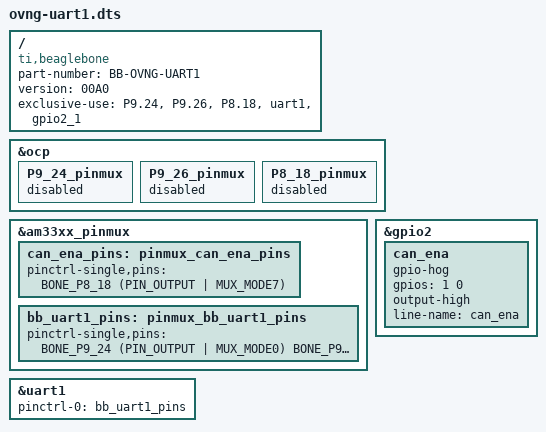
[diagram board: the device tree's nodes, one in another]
/*
 * Copyright (C) 2013 CircuitCo
 *
 * Virtual cape for UART1 on connector pins P9.24 P9.26
 *
 * This program is free software; you can redistribute it and/or modify
 * it under the terms of the GNU General Public License version 2 as
 * published by the Free Software Foundation.
 */

/dts-v1/;
/plugin/;

#include <dt-bindings/board/am335x-bbw-bbb-base.h>
#include <dt-bindings/pinctrl/am33xx.h>

/ {
	compatible = "ti,beaglebone", "ti,beaglebone-black", "ti,beaglebone-green", "ti,beaglebone-green-wireless";

	// identification
	part-number = "BB-OVNG-UART1";
	version = "00A0";

	// resources this cape uses
	exclusive-use =
		"P9.24",	// uart1_txd
		"P9.26",	// uart1_rxd
		"P8.18",	// gpio2_1: can_ena

		"uart1",	// hardware ip used
		"gpio2_1";

	/*
	 * Free up the pins used by the cape from the pinmux helpers.
	 */
	fragment@0 {
		target = <&ocp>;
		__overlay__ {
			P9_24_pinmux { status = "disabled"; };	/* P9_24: uart1_txd.d_can1_rx */
			P9_26_pinmux { status = "disabled"; };	/* P9_26: uart1_rxd.d_can1_tx */
			P8_18_pinmux { status = "disabled"; };	/* P8_18: gpio2_1 */
		};
	};

	fragment@1 {
		target = <&am33xx_pinmux>;
		__overlay__ {
			can_ena_pins: pinmux_can_ena_pins {
				pinctrl-single,pins = <
					BONE_P8_18 (PIN_OUTPUT | MUX_MODE7)	/* P8_18: gpio2_1 */
				>;
			};

			bb_uart1_pins: pinmux_bb_uart1_pins {
				pinctrl-single,pins = <
					BONE_P9_24 (PIN_OUTPUT | MUX_MODE0)	/* P9_24: uart1_txd.d_can1_rx */
					BONE_P9_26 (PIN_INPUT | MUX_MODE0)	/* P9_26: uart1_rxd.d_can1_tx */
				>;
			};
		};
	};

	fragment@2 {
		target = <&uart1>;
		__overlay__ {
			status = "okay";
			pinctrl-names = "default";
			pinctrl-0 = <&bb_uart1_pins>;
		};
	};

	fragment@3 {
		target = <&gpio2>;
		__overlay__ {
			can_ena {
				gpio-hog;
				gpios = <1 0>;
				output-high;
				line-name = "can_ena";
			};
		};
	};
};
